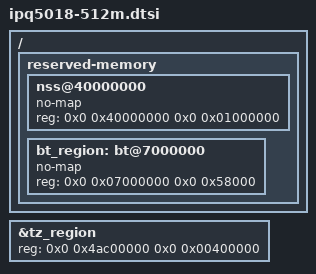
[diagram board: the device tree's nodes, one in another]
// SPDX-License-Identifier: GPL-2.0-only

#include "ipq5018.dtsi"
/ {
	reserved-memory {
		nss@40000000 {
			no-map;
			reg = <0x0 0x40000000 0x0 0x01000000>;
		};

		bt_region: bt@7000000 {
			no-map;
			reg = <0x0 0x07000000 0x0 0x58000>;
		};
	};
};

&tz_region {
    reg = <0x0 0x4ac00000 0x0 0x00400000>;
};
